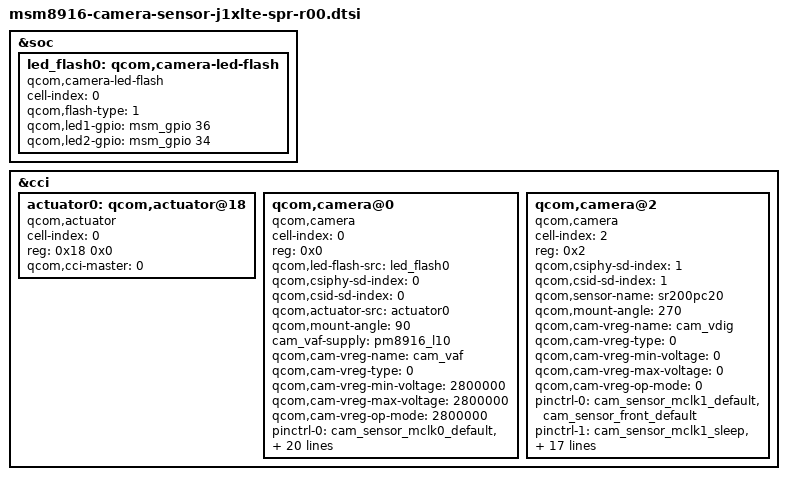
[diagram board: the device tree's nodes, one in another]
/*
 * Copyright (c) 2014, The Linux Foundation. All rights reserved.
 *
 * This program is free software; you can redistribute it and/or modify
 * it under the terms of the GNU General Public License version 2 and
 * only version 2 as published by the Free Software Foundation.
 *
 * This program is distributed in the hope that it will be useful,
 * but WITHOUT ANY WARRANTY; without even the implied warranty of
 * MERCHANTABILITY or FITNESS FOR A PARTICULAR PURPOSE.  See the
 * GNU General Public License for more details.
 */


&soc {
	led_flash0: qcom,camera-led-flash {
		cell-index = <0>;
		compatible = "qcom,camera-led-flash";
		qcom,flash-type = <1>;
		qcom,led1-gpio = <&msm_gpio 36 0x00>;
		qcom,led2-gpio = <&msm_gpio 34 0x00>;
	};
};


&cci {
	/* Dummy Actuator node to satisfy AF capabilities */
	actuator0: qcom,actuator@18 {
		compatible = "qcom,actuator";
		cell-index = <0>;
		reg = <0x18 0x0>;
		qcom,cci-master = <0>;
	};

	qcom,camera@0 {
		cell-index = <0>;
		compatible = "qcom,camera";
		reg = <0x0>;
		qcom,led-flash-src =<&led_flash0>;                              /* Temporarily remove FLASH */
		qcom,csiphy-sd-index = <0>;
		qcom,csid-sd-index = <0>;
		qcom,actuator-src = <&actuator0>;
		/*qcom,eeprom-src = <&eeprom0>;*/                                   /* No EEPROM */
		qcom,mount-angle = <90>;
		cam_vaf-supply = <&pm8916_l10>;
		qcom,cam-vreg-name = "cam_vaf";
		qcom,cam-vreg-type = <0>;
		qcom,cam-vreg-min-voltage = <2800000>;
		qcom,cam-vreg-max-voltage = <2800000>;
		qcom,cam-vreg-op-mode = <2800000>;
		pinctrl-names = "cam_default", "cam_suspend";
		pinctrl-0 = <&cam_sensor_mclk0_default &cam_core_en_default &cam_sensor_rear_default>;
		pinctrl-1 = <&cam_sensor_mclk0_sleep &cam_core_en_sleep &cam_sensor_rear_sleep>;
		gpios = <&msm_gpio 26 0>,/*MCLK*/
			<&msm_gpio 35 0>,/*RESET*/
			<&msm_gpio 8 0>,/*STANDBY*/
			<&msm_gpio 23 0>,/*VIO_EN*/
			<&msm_gpio 22 0>,/*A2P8_EN*/
            <&msm_gpio 33 0>;/*CAM_CORE*/
		qcom,gpio-reset = <1>;
		qcom,gpio-standby = <2>;
		qcom,gpio-ext-vio-power = <3>;
		qcom,gpio-ext-vana-power = <4>;
        qcom,gpio-vdig = <5>;
		qcom,gpio-req-tbl-num = <0 1 2 3 4 5>;
		qcom,gpio-req-tbl-flags = <1 0 0 0 0 0>;
		qcom,gpio-req-tbl-label = "CAMIF_MCLK",
					  "CAM_RESET1",
					  "CAM_STANDBY",
					  "CAM_IO_EN",
					  "CAM_ANALOG_EN",
					  "CAM_CORE_EN";
		qcom,sensor-position = <0>;
		qcom,sensor-mode = <0>;
		qcom,cci-master = <0>;
		status = "ok";
		clocks = <&clock_gcc clk_mclk0_clk_src>,
			   <&clock_gcc clk_gcc_camss_mclk0_clk>;
		clock-names = "cam_src_clk", "cam_clk";
	};

    qcom,camera@2 {
        cell-index = <2>;
        compatible = "qcom,camera";
        reg = <0x2>;
        qcom,csiphy-sd-index = <1>;
        qcom,csid-sd-index = <1>;
        qcom,sensor-name = "sr200pc20";
        qcom,mount-angle = <270>;
        qcom,cam-vreg-name = "cam_vdig";                        /* If this is left as NULL, it is a FAILURE.. So set all to 0, and make the entry */
        qcom,cam-vreg-type = <0>;
        qcom,cam-vreg-min-voltage = <0>;
        qcom,cam-vreg-max-voltage = <0>;
        qcom,cam-vreg-op-mode = <0>;
        pinctrl-names = "cam_default", "cam_suspend";
        pinctrl-0 = <&cam_sensor_mclk1_default &cam_sensor_front_default>;
        pinctrl-1 = <&cam_sensor_mclk1_sleep &cam_sensor_front_sleep>;
        gpios = <&msm_gpio 27 0>,   /* MCLK */
                <&msm_gpio 28 0>,               /* RST */
                <&msm_gpio 9 0>,               /* STANDBY */
                <&msm_gpio 23 0>,               /* VIO_EN 1P8 */
                <&msm_gpio 22 0>;               /* A2P8_EN */
        qcom,gpio-vt-reset = <1>;
        qcom,gpio-vt-standby = <2>;
        qcom,gpio-ext-vio-power = <3>;
        qcom,gpio-ext-vana-power = <4>;
        qcom,gpio-req-tbl-num = <0 1 2 3 4>;
        qcom,gpio-req-tbl-flags = <1 0 0 0 0>;
        qcom,gpio-req-tbl-label = "CAMIF_MCLK",
                "CAM_RESET",
                "CAM_STBY",
                "CAM_IO_EN",
                "CAM_ANALOG_EN";
        qcom,sensor-position = <1>;
        qcom,sensor-mode = <0>;
        qcom,cci-master = <0>;
        status = "ok";
        clocks = <&clock_gcc clk_mclk1_clk_src>,
                    <&clock_gcc clk_gcc_camss_mclk1_clk>;
        clock-names = "cam_src_clk", "cam_clk";
    };
};
